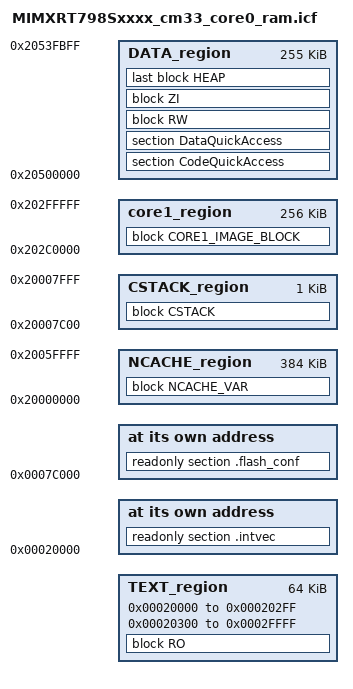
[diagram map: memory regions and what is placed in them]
/*
** ###################################################################
**     Processors:          MIMXRT798SGAWAR_cm33_core0
**                          MIMXRT798SGFOA_cm33_core0
**
**     Compiler:            IAR ANSI C/C++ Compiler for ARM
**     Reference manual:    iMXRT700RM Rev.1, 06/2023
**     Version:             rev. 1.0, 2022-08-01
**     Build:               b231012
**
**     Abstract:
**         Linker file for the IAR ANSI C/C++ Compiler for ARM
**
**     Copyright 2016 Freescale Semiconductor, Inc.
**     Copyright 2016-2023 NXP
**     SPDX-License-Identifier: BSD-3-Clause
**
**     http:                 www.nxp.com
**     mail:                 support@nxp.com
**
** ###################################################################
*/

/* Stack and Heap Sizes */
if (isdefinedsymbol(__stack_size__)) {
  define symbol __size_cstack__        = __stack_size__;
} else {
  define symbol __size_cstack__        = 0x0400;
}

if (isdefinedsymbol(__heap_size__)) {
  define symbol __size_heap__          = __heap_size__;
} else {
  define symbol __size_heap__          = 0x0400;
}

/* The SRAM region [0x0-0x7FFFF] is reserved for Non-cached shared memory between M33 and DSP. */


define symbol m_interrupts_start               = 0x00020000;
define symbol m_interrupts_end                 = 0x000202FF;

define symbol m_text_start                     = 0x00020300;
define symbol m_text_end                       = 0x0002FFFF;

define symbol m_data_start                     = 0x20500000;
define symbol m_data_end                       = 0x2053FFFF;

define symbol m_stack_start                    = 0x20000000;
define symbol m_stack_end                      = 0x20007FFF;

define symbol m_ncache_start                   = 0x20000000;
define symbol m_ncache_end                     = 0x2005FFFF;

define exported symbol core1_image_start       = 0x202C0000;
define exported symbol core1_image_end         = 0x202FFFFF;

define symbol m_boot_flash_conf_start          = 0x0007C000;

define exported symbol __VECTOR_TABLE          = m_interrupts_start;
define exported symbol __VECTOR_RAM            = m_interrupts_start;
define exported symbol __RAM_VECTOR_TABLE_SIZE = 0x0;

define exported symbol __NCACHE_REGION_START   = m_ncache_start;
define exported symbol __NCACHE_REGION_SIZE    = m_ncache_end - m_ncache_start + 1;

define memory mem with size = 4G;

define region TEXT_region             = mem:[from m_interrupts_start to m_interrupts_end]
                                      | mem:[from m_text_start to m_text_end];
define region DATA_region             = mem:[from m_data_start to m_data_end - __size_cstack__];
define region CSTACK_region           = mem:[from m_stack_end-__size_cstack__ + 1 to m_stack_end];
define region NCACHE_region           = mem:[from m_ncache_start to m_ncache_end];
define region core1_region = mem:[from core1_image_start to core1_image_end];
define block CORE1_IMAGE_BLOCK          { section  __core1_image };

define block CSTACK    with alignment = 8, size = __size_cstack__   { };
define block HEAP      with alignment = 8, size = __size_heap__     { };
define block RO        { readonly };
define block RW        { readwrite };
define block ZI        { zi };
define block NCACHE_VAR    { section NonCacheable , section NonCacheable.init };

initialize by copy { readwrite, section .textrw , section CodeQuickAccess, section DataQuickAccess, section  __core1_image };

do not initialize  { section .noinit };

keep{section .flash_conf };
place at address mem: m_boot_flash_conf_start    { readonly section .flash_conf };
place at address mem: m_interrupts_start    { readonly section .intvec };
place in TEXT_region                        { block RO };
place in DATA_region                        { section CodeQuickAccess, section DataQuickAccess };
place in DATA_region                        { block RW };
place in DATA_region                        { block ZI };
place in DATA_region                        { last block HEAP };
place in NCACHE_region                      { block NCACHE_VAR };
place in CSTACK_region                      { block CSTACK };
place in core1_region                       { block CORE1_IMAGE_BLOCK };
